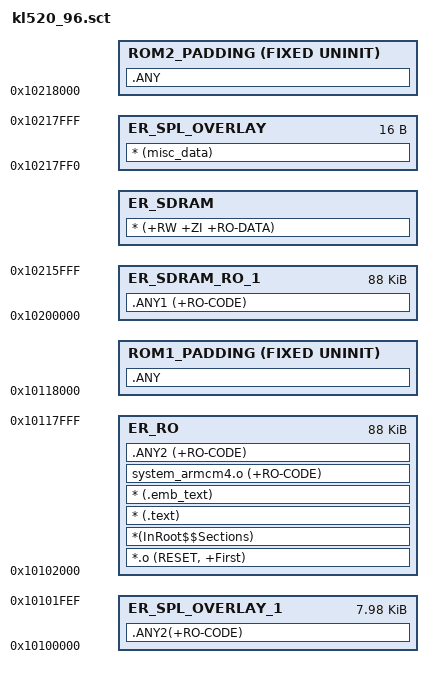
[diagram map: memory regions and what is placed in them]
#!armcc -E

; The goal of this scatter file is to have a maximize utilization of S-iRAM for CODE-only
; to do this, it seems to need 2+ load regions

; S-iRAM SPL 8KB, it will be override when doing scatter-loading
#define S_SPL_START 0x10100000
#define S_SPL_SIZE  0x00002000

; S-iRAM start address after SPL 8KB
#define S_IRAM_START 0x10102000
#define S_IRAM_SIZE  0x00016000
#define S_IRAM_END   0x10118000

; S-dRAM start address
#define S_DRAM_START    0x10200000
#define S_DRAM_SIZE     0x18000
#define S_DRAM_END      0x10218000
#define IPC_SIZE        0x2000


; S-iRAM load region
; SPL should copy the code part from flash into this
LR_FROM_SIRAM S_IRAM_START S_IRAM_SIZE  {

    ; code
    ER_RO S_IRAM_START ANY_SIZE S_IRAM_SIZE-0X200 S_IRAM_SIZE  {
        *.o (RESET, +First)
        *(InRoot$$Sections)
        * (.text)
        * (.emb_text)
        ; startup_armcm4.o (+RO-CODE)
        system_armcm4.o (+RO-CODE)
        .ANY2 (+RO-CODE)
    }
    
    ROM1_PADDING S_IRAM_END FIXED PADVALUE 0x0 UNINIT {.ANY}
}

LR_FROM_SDRAM_2 S_DRAM_END-S_SPL_SIZE S_SPL_SIZE {

    ER_SPL_OVERLAY S_DRAM_END-0x10 0x10 {
        * (misc_data)
    }

    ER_SPL_OVERLAY_1 S_SPL_START ANY_SIZE S_SPL_SIZE-0X100 S_SPL_SIZE-0x10 {
        .ANY2(+RO-CODE)
    }

    ROM2_PADDING S_DRAM_END FIXED PADVALUE 0x0 UNINIT {.ANY}
}

LR_FROM_SDRAM S_DRAM_START S_DRAM_SIZE-S_SPL_SIZE {

    ER_SDRAM_RO_1 S_DRAM_START S_DRAM_SIZE-S_SPL_SIZE {
        .ANY1 (+RO-CODE)
    }

    ; load RW/RO-DATA/ZI to the S-dRAM
    ER_SDRAM ImageLimit(ER_SDRAM_RO_1) S_DRAM_SIZE - IPC_SIZE- ImageLength(ER_SDRAM_RO_1) {
        * (+RW +ZI +RO-DATA)
    }
    
    ;ROM3_PADDING S_DRAM_END-S_SPL_SIZE FIXED PADVALUE 0x0 UNINIT {.ANY}
}
